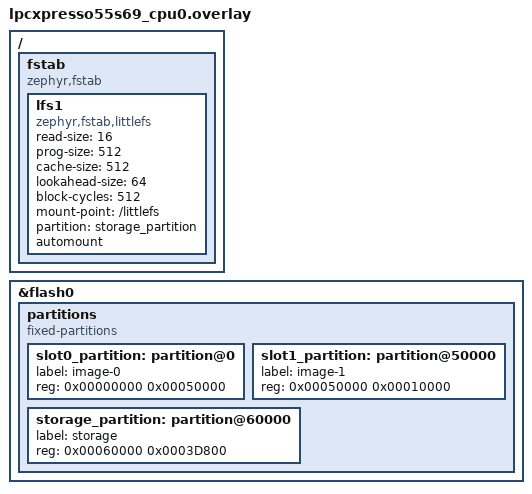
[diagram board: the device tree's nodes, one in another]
/delete-node/ &slot0_partition;
/delete-node/ &slot1_partition;
/delete-node/ &slot2_partition;
/delete-node/ &slot3_partition;
/delete-node/ &storage_partition;
/delete-node/ &boot_partition;

/ {
	fstab {
		compatible = "zephyr,fstab";

		// https://docs.zephyrproject.org/latest/build/dts/api/bindings/fs/zephyr,fstab,littlefs.html
		lfs1: lfs1 {
			compatible = "zephyr,fstab,littlefs";
			read-size = <16>;
			prog-size = <512>;
			cache-size = <512>;
			lookahead-size = <64>;
			block-cycles = <512>;
			mount-point = "/littlefs";
			partition = <&storage_partition>;
			automount;
			// read-only;
			// no-format;
			// disk-access;
    };
	};
};

&flash0 {
	partitions {
		compatible = "fixed-partitions";
		#address-cells = <1>;
		#size-cells = <1>;

		// 320 KB 
		slot0_partition: partition@0 {
			label = "image-0";
			reg = <0x00000000 0x00050000>;
		};

		// 64 KB
		slot1_partition: partition@50000 {
			label = "image-1";
			reg = <0x00050000 0x00010000>;
		};

		// 246 KB
		storage_partition: partition@60000 {
			label = "storage";
			reg = <0x00060000 0x0003D800>;
		};
	};
};
